VERSION ""

NS_ :

BS_:

BU_: XXX +

BO_ 277 NEW_MSG_1: 8 XXX
 SG_ Gear : 49|2@0+ (1,0) [0|1] "" XXX
 SG_ N2 : 33|2@0+ (1,0) [0|1] "" XXX
 SG_ NDS : 25|2@0+ (1,0) [0|1] "" XXX
 SG_ R : 31|3@0+ (1,0) [0|1] "" XXX
 SG_ S : 58|1@0+ (1,0) [0|1] "" XXX
 SG_ Gas : 38|7@0+ (1,0) [0|1] "" XXX

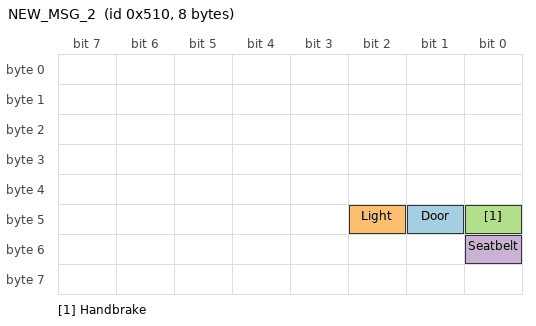
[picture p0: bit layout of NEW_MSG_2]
BO_ 1296 NEW_MSG_2: 8 XXX
 SG_ Door : 41|1@0+ (1,0) [0|1] "" XXX
 SG_ Light : 42|1@0+ (1,0) [0|1] "" XXX
 SG_ Handbrake : 40|1@0+ (1,0) [0|1] "" XXX
 SG_ Seatbelt : 48|1@0+ (1,0) [0|1] "" XXX

BO_ 864 NEW_MSG_3: 8 XXX
 SG_ P : 41|2@0+ (1,0) [0|1] "" XXX

BO_ 257 NEW_MSG_4: 8 XXX
 SG_ BrakePressure : 56|1@0+ (1,0) [0|1] "" XXX

CM_ SG_ 277 R "0 when R";
CM_ SG_ 864 P "0 when P";
